AUTOSAR XML (schema 00045)
package /AebDs
  swc implementation AbsDsImpl: programming-language=C, sw-version=0.0.1, vendor-id=0, behavior=AebDs_IB
    code-descriptors:
      code CodeGen: artifact-descriptors=[{short-label=SWHDR, category=SWHDR}, {short-label=SWSRC, category=SWSRC}]
    resource consumption Resource
      memory section CODE: sw-addrmethod=CODE
      memory section VAR_UNSPECIFIED: sw-addrmethod=VAR
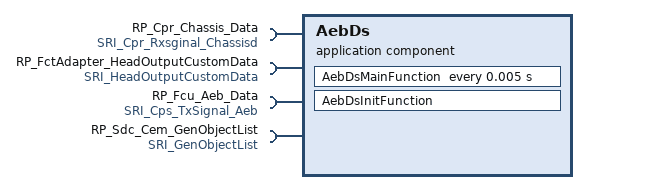
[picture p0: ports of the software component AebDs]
  application sw component type AebDs  # AEBDataStorage
    4 x require port:
      RP_Cpr_Chassis_Data: required-interface=SRI_Cpr_Rxsginal_Chassisd
      RP_FctAdapter_HeadOutputCustomData: required-interface=SRI_HeadOutputCustomData
      RP_Fcu_Aeb_Data: required-interface=SRI_Cps_TxSignal_Aeb
      RP_Sdc_Cem_GenObjectList: required-interface=SRI_GenObjectList
    behavior AebDs_IB: handle-termination-and-restart=NO-SUPPORT
      init event InitEvent_AebDs_InitFunction: start-on-event=AebDsInitFunction
      timing event TimingEvent_AebDs_MainFunction: start-on-event=AebDsMainFunction, period=0.005
      runnable AebDsInitFunction
        data-receive-point-by-arguments:
          access drparg_GenObjectList: accessed-variable=RP_Sdc_Cem_GenObjectList.GenObjectList
          access drparg_HeadOutputCustomData: accessed-variable=RP_FctAdapter_HeadOutputCustomData.HeadOutputCustomData
      runnable AebDsMainFunction
        data-receive-point-by-arguments:
          19 x access:
            drparg_Cps_SignalPhyData_FC_: accessed-variable=RP_Fcu_Aeb_Data.Cps_SignalPhyData_FC_FCWActive
            drparg_Cps_SignalPhyData_FC_0: accessed-variable=RP_Fcu_Aeb_Data.Cps_SignalPhyData_FC_AWBActive
            drparg_Cps_SignalPhyData_FC_1: accessed-variable=RP_Fcu_Aeb_Data.Cps_SignalPhyData_FC_AEBActive
            drparg_Cps_SignalPhyData_FC_2: accessed-variable=RP_Fcu_Aeb_Data.Cps_SignalPhyData_FC_AEBTargetRelSpeed
            drparg_Cps_SignalPhyData_FC_3: accessed-variable=RP_Fcu_Aeb_Data.Cps_SignalPhyData_FC_AEBTargetLatRange
            drparg_Cps_SignalPhyData_FC_4: accessed-variable=RP_Fcu_Aeb_Data.Cps_SignalPhyData_FC_AEBTargetLngRange
            drparg_Cps_SignalPhyData_FC_5: accessed-variable=RP_Fcu_Aeb_Data.Cps_SignalPhyData_FC_AEBTargetAx
            drparg_Cps_SignalPhyData_FC_6: accessed-variable=RP_Fcu_Aeb_Data.Cps_SignalPhyData_FC_AEBTargetLatRelSpeed
            drparg_Cps_SignalPhyData_FC_7: accessed-variable=RP_Fcu_Aeb_Data.Cps_SignalPhyData_FC_AEBTargetAy
            drparg_EpsSasSteerAg: accessed-variable=RP_Cpr_Chassis_Data.EpsSasSteerAg
            drparg_EpsSteerAgRate: accessed-variable=RP_Cpr_Chassis_Data.EpsSteerAgRate
            drparg_EspLatAccel: accessed-variable=RP_Cpr_Chassis_Data.EspLatAccel
            drparg_EspLongAccel: accessed-variable=RP_Cpr_Chassis_Data.EspLongAccel
            drparg_EspVehSpd: accessed-variable=RP_Cpr_Chassis_Data.EspVehSpd
            drparg_EspYawRate: accessed-variable=RP_Cpr_Chassis_Data.EspYawRate
            drparg_GenObjectList: accessed-variable=RP_Sdc_Cem_GenObjectList.GenObjectList
            drparg_HeadOutputCustomData: accessed-variable=RP_FctAdapter_HeadOutputCustomData.HeadOutputCustomData
            drparg_PlungerBrakePressure: accessed-variable=RP_Cpr_Chassis_Data.PlungerBrakePressure
            drparg_VcuAccrPedlPosn: accessed-variable=RP_Cpr_Chassis_Data.VcuAccrPedlPosn
